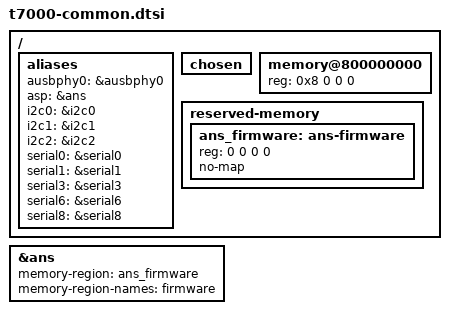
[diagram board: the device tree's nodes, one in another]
// SPDX-License-Identifier: GPL-2.0+ OR MIT
/*
 * Apple TV HD, iPhone 6, iPhone 6 Plus, iPad mini 4, iPod touch 6
 *
 * This file contains parts common to all Apple A8 devices.
 *
 * target-type: J42d, J96, J97, N56, N61, N102
 *
 * Copyright (c) 2024, Nick Chan <towinchenmi@gmail.com>
 */

/ {
	aliases {
		ausbphy0 = &ausbphy0; /* Used by loader */
		asp = &ans;
		i2c0 = &i2c0;
		i2c1 = &i2c1;
		i2c2 = &i2c2;
		serial0 = &serial0;
		serial1 = &serial1;
		serial3 = &serial3;
		serial6 = &serial6;
		serial8 = &serial8;
	};

	chosen {
		#address-cells = <2>;
		#size-cells = <2>;
		ranges;
	};

	memory@800000000 {
		device_type = "memory";
		reg = <0x8 0 0 0>; /* To be filled by loader */
	};

	reserved-memory {
		#address-cells = <2>;
		#size-cells = <2>;
		ranges;

		ans_firmware: ans-firmware {
			/* Filled in by bootloder */
			reg = <0 0 0 0>;
			no-map;
		};
		/* To be filled by loader */
	};
};

&ans {
	memory-region = <&ans_firmware>;
	memory-region-names = "firmware";
	status = "okay";
};
